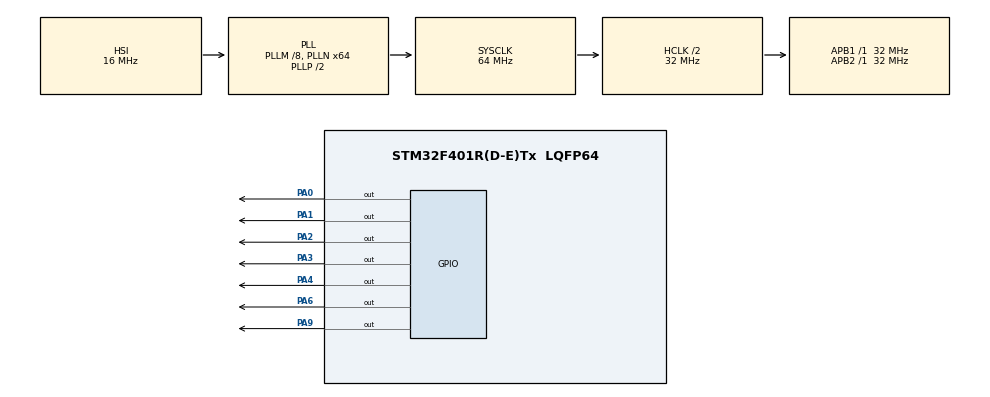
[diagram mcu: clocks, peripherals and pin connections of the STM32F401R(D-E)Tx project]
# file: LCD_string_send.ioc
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Mcu.Family=STM32F4
Mcu.Name=STM32F401R(D-E)Tx
Mcu.Package=LQFP64
NVIC.PriorityGroup=NVIC_PRIORITYGROUP_4
PA0-WKUP.Signal=GPIO_Output
PA1.Signal=GPIO_Output
PA13.Mode=Serial_Wire
PA13.Signal=SYS_JTMS-SWDIO
PA14.Mode=Serial_Wire
PA14.Signal=SYS_JTCK-SWCLK
PA2.Signal=GPIO_Output
PA3.Signal=GPIO_Output
PA4.Signal=GPIO_Output
PA6.Signal=GPIO_Output
PA9.Signal=GPIO_Output
PH0\ -\ OSC_IN.Mode=HSE-External-Clock-Source
PH0\ -\ OSC_IN.Signal=RCC_OSC_IN
PH1\ -\ OSC_OUT.Mode=HSE-External-Clock-Source
PH1\ -\ OSC_OUT.Signal=RCC_OSC_OUT
ProjectManager.HeapSize=0x200
ProjectManager.StackSize=0x400
ProjectManager.TargetToolchain=STM32CubeIDE
RCC.48MHZClocksFreq_Value=32000000
RCC.AHBCLKDivider=RCC_SYSCLK_DIV2
RCC.AHBFreq_Value=32000000
RCC.APB1Freq_Value=32000000
RCC.APB1TimFreq_Value=32000000
RCC.APB2Freq_Value=32000000
RCC.APB2TimFreq_Value=32000000
RCC.CortexFreq_Value=32000000
RCC.HCLKFreq_Value=32000000
RCC.HSE_VALUE=8000000
RCC.HSI_VALUE=16000000
RCC.LSE_VALUE=32768
RCC.PLLM=8
RCC.PLLN=64
RCC.SYSCLKFreq_VALUE=64000000
RCC.SYSCLKSource=RCC_SYSCLKSOURCE_PLLCLK
RCC.VCOOutputFreq_Value=128000000
board=custom

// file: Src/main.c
/* USER CODE BEGIN Header */
/**
  ******************************************************************************
  * @file           : main.c
  * @brief          : Main program body
  ******************************************************************************
  * @attention
  *
  * <h2><center>&copy; Copyright (c) 2021 STMicroelectronics.
  * All rights reserved.</center></h2>
  *
  * This software component is licensed by ST under BSD 3-Clause license,
  * the "License"; You may not use this file except in compliance with the
  * License. You may obtain a copy of the License at:
  *                        opensource.org/licenses/BSD-3-Clause
  *
  ******************************************************************************
  */
/* USER CODE END Header */
#include "main.h"

/* USER CODE BEGIN Includes */
#include "lcd.h"

/* USER CODE END Includes */

void SystemClock_Config(void);
static void MX_GPIO_Init(void);

int main(void)
{

  /* MCU Configuration--------------------------------------------------------*/

  /* Reset of all peripherals, Initializes the Flash interface and the Systick. */
  HAL_Init();

  /* Configure the system clock */
  SystemClock_Config();

  /* Initialize all configured peripherals */
  MX_GPIO_Init();
  /* USER CODE BEGIN 2 */

  lcd_init();
  lcd_set_cursor(0,0);

  HAL_Delay(500);
  lcd_send_data("Mithlesh");

  /* USER CODE END 2 */

  /* Infinite loop */
  while (1)
  {

  }
}

void SystemClock_Config(void)
{
  RCC_OscInitTypeDef RCC_OscInitStruct = {0};
  RCC_ClkInitTypeDef RCC_ClkInitStruct = {0};

  /** Configure the main internal regulator output voltage
  */
  __HAL_RCC_PWR_CLK_ENABLE();
  __HAL_PWR_VOLTAGESCALING_CONFIG(PWR_REGULATOR_VOLTAGE_SCALE2);
  /** Initializes the RCC Oscillators according to the specified parameters
  * in the RCC_OscInitTypeDef structure.
  */
  RCC_OscInitStruct.OscillatorType = RCC_OSCILLATORTYPE_HSI;
  RCC_OscInitStruct.HSIState = RCC_HSI_ON;
  RCC_OscInitStruct.HSICalibrationValue = RCC_HSICALIBRATION_DEFAULT;
  RCC_OscInitStruct.PLL.PLLState = RCC_PLL_ON;
  RCC_OscInitStruct.PLL.PLLSource = RCC_PLLSOURCE_HSI;
  RCC_OscInitStruct.PLL.PLLM = 8;
  RCC_OscInitStruct.PLL.PLLN = 64;
  RCC_OscInitStruct.PLL.PLLP = RCC_PLLP_DIV2;
  RCC_OscInitStruct.PLL.PLLQ = 4;
  if (HAL_RCC_OscConfig(&RCC_OscInitStruct) != HAL_OK)
  {
    Error_Handler();
  }
  /** Initializes the CPU, AHB and APB buses clocks
  */
  RCC_ClkInitStruct.ClockType = RCC_CLOCKTYPE_HCLK|RCC_CLOCKTYPE_SYSCLK
                              |RCC_CLOCKTYPE_PCLK1|RCC_CLOCKTYPE_PCLK2;
  RCC_ClkInitStruct.SYSCLKSource = RCC_SYSCLKSOURCE_PLLCLK;
  RCC_ClkInitStruct.AHBCLKDivider = RCC_SYSCLK_DIV2;
  RCC_ClkInitStruct.APB1CLKDivider = RCC_HCLK_DIV1;
  RCC_ClkInitStruct.APB2CLKDivider = RCC_HCLK_DIV1;

  if (HAL_RCC_ClockConfig(&RCC_ClkInitStruct, FLASH_LATENCY_1) != HAL_OK)
  {
    Error_Handler();
  }
}

static void MX_GPIO_Init(void)
{
  GPIO_InitTypeDef GPIO_InitStruct = {0};

  /* GPIO Ports Clock Enable */
  __HAL_RCC_GPIOH_CLK_ENABLE();
  __HAL_RCC_GPIOA_CLK_ENABLE();

  /*Configure GPIO pin Output Level */
  HAL_GPIO_WritePin(GPIOA, GPIO_PIN_0|GPIO_PIN_1|GPIO_PIN_2|GPIO_PIN_3
                          |GPIO_PIN_4|GPIO_PIN_6|GPIO_PIN_9, GPIO_PIN_RESET);

  /*Configure GPIO pins : PA0 PA1 PA2 PA3
                           PA4 PA6 PA9 */
  GPIO_InitStruct.Pin = GPIO_PIN_0|GPIO_PIN_1|GPIO_PIN_2|GPIO_PIN_3
                          |GPIO_PIN_4|GPIO_PIN_6|GPIO_PIN_9;
  GPIO_InitStruct.Mode = GPIO_MODE_OUTPUT_PP;
  GPIO_InitStruct.Pull = GPIO_NOPULL;
  GPIO_InitStruct.Speed = GPIO_SPEED_FREQ_LOW;
  HAL_GPIO_Init(GPIOA, &GPIO_InitStruct);

}

void Error_Handler(void)
{
  __disable_irq();
  while (1)
  {
  }
}

/************************ (C) COPYRIGHT STMicroelectronics *****END OF FILE****/
